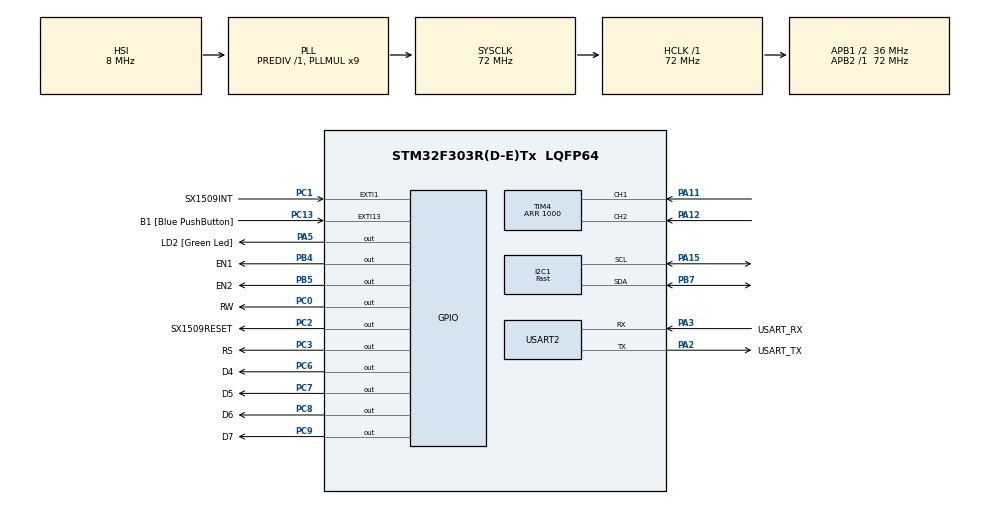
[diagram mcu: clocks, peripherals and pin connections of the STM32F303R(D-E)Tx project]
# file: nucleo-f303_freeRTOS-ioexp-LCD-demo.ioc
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ADC1.Channel-0\#ChannelRegularConversion=ADC_CHANNEL_TEMPSENSOR
ADC1.EnableInjectedConversion=DISABLE
ADC1.NbrOfConversionFlag=1
ADC1.Offset-0\#ChannelRegularConversion=0
ADC1.OffsetNumber-0\#ChannelRegularConversion=ADC_OFFSET_NONE
ADC1.Rank-0\#ChannelRegularConversion=1
ADC1.SamplingTime-0\#ChannelRegularConversion=ADC_SAMPLETIME_181CYCLES_5
ADC1.master=1
FREERTOS.Tasks01=defaultTask,24,128,StartDefaultTask,Default,NULL,Dynamic,NULL,NULL
FREERTOS.configTOTAL_HEAP_SIZE=8096
I2C1.I2C_Speed_Mode=I2C_Fast
I2C1.Timing=0x0000020B
Mcu.Family=STM32F3
Mcu.Name=STM32F303R(D-E)Tx
Mcu.Package=LQFP64
NVIC.ADC1_2_IRQn=true\:5\:0\:false\:false\:true\:true\:true\:true
NVIC.PriorityGroup=NVIC_PRIORITYGROUP_4
NVIC.TIM2_IRQn=true\:5\:0\:false\:false\:true\:true\:true\:true
NVIC.TIM4_IRQn=true\:5\:0\:false\:false\:true\:true\:true\:true
NVIC.TIM6_DAC_IRQn=true\:0\:0\:false\:false\:true\:false\:false\:true
NVIC.TimeBase=TIM6_DAC_IRQn
NVIC.TimeBaseIP=TIM6
PA11.Signal=S_TIM4_CH1
PA12.Signal=S_TIM4_CH2
PA13.GPIO_Label=TMS
PA13.Mode=Serial_Wire
PA13.Signal=SYS_JTMS-SWDIO
PA14.GPIO_Label=TCK
PA14.Mode=Serial_Wire
PA14.Signal=SYS_JTCK-SWCLK
PA15.Mode=I2C
PA15.Signal=I2C1_SCL
PA2.GPIO_Label=USART_TX
PA2.GPIO_Mode=GPIO_MODE_AF_PP
PA2.GPIO_PuPd=GPIO_NOPULL
PA2.GPIO_Speed=GPIO_SPEED_FREQ_LOW
PA2.Mode=Asynchronous
PA2.Signal=USART2_TX
PA3.GPIO_Label=USART_RX
PA3.GPIO_Mode=GPIO_MODE_AF_PP
PA3.GPIO_PuPd=GPIO_NOPULL
PA3.GPIO_Speed=GPIO_SPEED_FREQ_LOW
PA3.Mode=Asynchronous
PA3.Signal=USART2_RX
PA5.GPIO_Label=LD2 [Green Led]
PA5.GPIO_Mode=GPIO_MODE_OUTPUT_PP
PA5.GPIO_PuPd=GPIO_NOPULL
PA5.GPIO_Speed=GPIO_SPEED_FREQ_LOW
PA5.Signal=GPIO_Output
PB3.GPIO_Label=SWO
PB3.Signal=SYS_JTDO-TRACESWO
PB4.GPIO_Label=EN1
PB4.Signal=GPIO_Output
PB5.GPIO_Label=EN2
PB5.Signal=GPIO_Output
PB7.Mode=I2C
PB7.Signal=I2C1_SDA
PC0.GPIO_Label=RW
PC0.Signal=GPIO_Output
PC1.GPIO_Label=SX1509INT
PC1.GPIO_ModeDefaultEXTI=GPIO_MODE_IT_FALLING
PC1.Signal=GPXTI1
PC13.GPIO_Label=B1 [Blue PushButton]
PC13.GPIO_ModeDefaultEXTI=GPIO_MODE_IT_FALLING
PC13.Signal=GPXTI13
PC14-OSC32_IN.Mode=LSE-External-Oscillator
PC14-OSC32_IN.Signal=RCC_OSC32_IN
PC15-OSC32_OUT.Mode=LSE-External-Oscillator
PC15-OSC32_OUT.Signal=RCC_OSC32_OUT
PC2.GPIO_Label=SX1509RESET
PC2.Signal=GPIO_Output
PC3.GPIO_Label=RS
PC3.Signal=GPIO_Output
PC6.GPIO_Label=D4
PC6.Signal=GPIO_Output
PC7.GPIO_Label=D5
PC7.Signal=GPIO_Output
PC8.GPIO_Label=D6
PC8.Signal=GPIO_Output
PC9.GPIO_Label=D7
PC9.Signal=GPIO_Output
PF0-OSC_IN.Mode=HSE-External-Clock-Source
PF0-OSC_IN.Signal=RCC_OSC_IN
PF1-OSC_OUT.Signal=RCC_OSC_OUT
ProjectManager.HeapSize=0x200
ProjectManager.StackSize=0x400
ProjectManager.TargetToolchain=STM32CubeIDE
RCC.AHBFreq_Value=72000000
RCC.APB1CLKDivider=RCC_HCLK_DIV2
RCC.APB1Freq_Value=36000000
RCC.APB1TimFreq_Value=72000000
RCC.APB2Freq_Value=72000000
RCC.APB2TimFreq_Value=72000000
RCC.CortexFreq_Value=72000000
RCC.HCLKFreq_Value=72000000
RCC.HSE_VALUE=8000000
RCC.HSI_VALUE=8000000
RCC.PLLM=8
RCC.PLLMUL=RCC_PLL_MUL9
RCC.PLLN=336
RCC.PLLP=RCC_PLLP_DIV4
RCC.PLLQ=7
RCC.RCC_PLLsource_Clock_Source_FROM_HSE=RCC_HSE_PREDIV_DIV2
RCC.SYSCLKFreq_VALUE=72000000
RCC.SYSCLKSourceVirtual=RCC_SYSCLKSOURCE_PLLCLK
RCC.USBFreq_Value=72000000
SH.S_TIM4_CH1.0=TIM4_CH1,Encoder_Interface
SH.S_TIM4_CH2.0=TIM4_CH2,Encoder_Interface
TIM2.Period=10000
TIM2.Prescaler=7200
TIM2.TIM_MasterOutputTrigger=TIM_TRGO_UPDATE
TIM4.IC1Filter=5
TIM4.IC2Filter=5
TIM4.Period=1000
USART2.VirtualMode-Asynchronous=VM_ASYNC
VP_ADC1_TempSens_Input.Mode=IN-TempSens
VP_FREERTOS_VS_CMSIS_V2.Mode=CMSIS_V2
VP_SYS_VS_tim6.Mode=TIM6
VP_TIM2_VS_ClockSourceINT.Mode=Internal
board=NUCLEO-F303RE

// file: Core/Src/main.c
/* USER CODE BEGIN Header */
/**
  ******************************************************************************
  * @file           : main.c
  * @brief          : Main program body
  ******************************************************************************
  * @attention
  *
  * <h2><center>&copy; Copyright (c) 2020 STMicroelectronics.
  * All rights reserved.</center></h2>
  *
  * This software component is licensed by ST under BSD 3-Clause license,
  * the "License"; You may not use this file except in compliance with the
  * License. You may obtain a copy of the License at:
  *                        opensource.org/licenses/BSD-3-Clause
  *
  ******************************************************************************
  */
/* USER CODE END Header */

#include "main.h"
#include "cmsis_os.h"

ADC_HandleTypeDef hadc1;

I2C_HandleTypeDef hi2c1;

TIM_HandleTypeDef htim2;
TIM_HandleTypeDef htim4;

UART_HandleTypeDef huart2;

/* Definitions for defaultTask */
osThreadId_t defaultTaskHandle;
const osThreadAttr_t defaultTask_attributes = {
  .name = "defaultTask",
  .priority = (osPriority_t) osPriorityNormal,
  .stack_size = 128 * 4
};
/* USER CODE BEGIN PV */
	int32_t encCount;
/* USER CODE END PV */

void SystemClock_Config(void);
static void MX_GPIO_Init(void);
static void MX_USART2_UART_Init(void);
static void MX_TIM4_Init(void);
static void MX_TIM2_Init(void);
static void MX_ADC1_Init(void);
static void MX_I2C1_Init(void);
void StartDefaultTask(void *argument);

int main(void)
{

  /* MCU Configuration--------------------------------------------------------*/

  /* Reset of all peripherals, Initializes the Flash interface and the Systick. */
  HAL_Init();

  /* Configure the system clock */
  SystemClock_Config();

  /* Initialize all configured peripherals */
  MX_GPIO_Init();
  MX_USART2_UART_Init();
  MX_TIM4_Init();
  MX_TIM2_Init();
  MX_ADC1_Init();
  MX_I2C1_Init();
  /* USER CODE BEGIN 2 */
  HAL_TIM_Encoder_Start_IT(&htim4, TIM_CHANNEL_ALL);
  /* USER CODE END 2 */

  /* Init scheduler */
  osKernelInitialize();

  /* Create the thread(s) */
  /* creation of defaultTask */
  defaultTaskHandle = osThreadNew(StartDefaultTask, NULL, &defaultTask_attributes);

  /* Start scheduler */
  osKernelStart();

  /* We should never get here as control is now taken by the scheduler */
  /* Infinite loop */
  while (1)
  {

  }
}

void SystemClock_Config(void)
{
  RCC_OscInitTypeDef RCC_OscInitStruct = {0};
  RCC_ClkInitTypeDef RCC_ClkInitStruct = {0};
  RCC_PeriphCLKInitTypeDef PeriphClkInit = {0};

  /** Initializes the CPU, AHB and APB busses clocks
  */
  RCC_OscInitStruct.OscillatorType = RCC_OSCILLATORTYPE_HSI;
  RCC_OscInitStruct.HSIState = RCC_HSI_ON;
  RCC_OscInitStruct.HSICalibrationValue = RCC_HSICALIBRATION_DEFAULT;
  RCC_OscInitStruct.PLL.PLLState = RCC_PLL_ON;
  RCC_OscInitStruct.PLL.PLLSource = RCC_PLLSOURCE_HSI;
  RCC_OscInitStruct.PLL.PLLMUL = RCC_PLL_MUL9;
  RCC_OscInitStruct.PLL.PREDIV = RCC_PREDIV_DIV1;
  if (HAL_RCC_OscConfig(&RCC_OscInitStruct) != HAL_OK)
  {
    Error_Handler();
  }
  /** Initializes the CPU, AHB and APB busses clocks
  */
  RCC_ClkInitStruct.ClockType = RCC_CLOCKTYPE_HCLK|RCC_CLOCKTYPE_SYSCLK
                              |RCC_CLOCKTYPE_PCLK1|RCC_CLOCKTYPE_PCLK2;
  RCC_ClkInitStruct.SYSCLKSource = RCC_SYSCLKSOURCE_PLLCLK;
  RCC_ClkInitStruct.AHBCLKDivider = RCC_SYSCLK_DIV1;
  RCC_ClkInitStruct.APB1CLKDivider = RCC_HCLK_DIV2;
  RCC_ClkInitStruct.APB2CLKDivider = RCC_HCLK_DIV1;

  if (HAL_RCC_ClockConfig(&RCC_ClkInitStruct, FLASH_LATENCY_2) != HAL_OK)
  {
    Error_Handler();
  }
  PeriphClkInit.PeriphClockSelection = RCC_PERIPHCLK_USART2|RCC_PERIPHCLK_I2C1
                              |RCC_PERIPHCLK_ADC12|RCC_PERIPHCLK_TIM2
                              |RCC_PERIPHCLK_TIM34;
  PeriphClkInit.Usart2ClockSelection = RCC_USART2CLKSOURCE_PCLK1;
  PeriphClkInit.Adc12ClockSelection = RCC_ADC12PLLCLK_DIV1;
  PeriphClkInit.I2c1ClockSelection = RCC_I2C1CLKSOURCE_HSI;
  PeriphClkInit.Tim2ClockSelection = RCC_TIM2CLK_HCLK;
  PeriphClkInit.Tim34ClockSelection = RCC_TIM34CLK_HCLK;
  if (HAL_RCCEx_PeriphCLKConfig(&PeriphClkInit) != HAL_OK)
  {
    Error_Handler();
  }
}

static void MX_ADC1_Init(void)
{

  ADC_MultiModeTypeDef multimode = {0};
  ADC_ChannelConfTypeDef sConfig = {0};

  /** Common config
  */
  hadc1.Instance = ADC1;
  hadc1.Init.ClockPrescaler = ADC_CLOCK_ASYNC_DIV1;
  hadc1.Init.Resolution = ADC_RESOLUTION_12B;
  hadc1.Init.ScanConvMode = ADC_SCAN_DISABLE;
  hadc1.Init.ContinuousConvMode = DISABLE;
  hadc1.Init.DiscontinuousConvMode = DISABLE;
  hadc1.Init.ExternalTrigConvEdge = ADC_EXTERNALTRIGCONVEDGE_NONE;
  hadc1.Init.ExternalTrigConv = ADC_SOFTWARE_START;
  hadc1.Init.DataAlign = ADC_DATAALIGN_RIGHT;
  hadc1.Init.NbrOfConversion = 1;
  hadc1.Init.DMAContinuousRequests = DISABLE;
  hadc1.Init.EOCSelection = ADC_EOC_SINGLE_CONV;
  hadc1.Init.LowPowerAutoWait = DISABLE;
  hadc1.Init.Overrun = ADC_OVR_DATA_OVERWRITTEN;
  if (HAL_ADC_Init(&hadc1) != HAL_OK)
  {
    Error_Handler();
  }
  /** Configure the ADC multi-mode
  */
  multimode.Mode = ADC_MODE_INDEPENDENT;
  if (HAL_ADCEx_MultiModeConfigChannel(&hadc1, &multimode) != HAL_OK)
  {
    Error_Handler();
  }
  /** Configure Regular Channel
  */
  sConfig.Channel = ADC_CHANNEL_TEMPSENSOR;
  sConfig.Rank = ADC_REGULAR_RANK_1;
  sConfig.SingleDiff = ADC_SINGLE_ENDED;
  sConfig.SamplingTime = ADC_SAMPLETIME_181CYCLES_5;
  sConfig.OffsetNumber = ADC_OFFSET_NONE;
  sConfig.Offset = 0;
  if (HAL_ADC_ConfigChannel(&hadc1, &sConfig) != HAL_OK)
  {
    Error_Handler();
  }

}

static void MX_I2C1_Init(void)
{

  hi2c1.Instance = I2C1;
  hi2c1.Init.Timing = 0x0000020B;
  hi2c1.Init.OwnAddress1 = 0;
  hi2c1.Init.AddressingMode = I2C_ADDRESSINGMODE_7BIT;
  hi2c1.Init.DualAddressMode = I2C_DUALADDRESS_DISABLE;
  hi2c1.Init.OwnAddress2 = 0;
  hi2c1.Init.OwnAddress2Masks = I2C_OA2_NOMASK;
  hi2c1.Init.GeneralCallMode = I2C_GENERALCALL_DISABLE;
  hi2c1.Init.NoStretchMode = I2C_NOSTRETCH_DISABLE;
  if (HAL_I2C_Init(&hi2c1) != HAL_OK)
  {
    Error_Handler();
  }
  /** Configure Analogue filter
  */
  if (HAL_I2CEx_ConfigAnalogFilter(&hi2c1, I2C_ANALOGFILTER_ENABLE) != HAL_OK)
  {
    Error_Handler();
  }
  /** Configure Digital filter
  */
  if (HAL_I2CEx_ConfigDigitalFilter(&hi2c1, 0) != HAL_OK)
  {
    Error_Handler();
  }

}

static void MX_TIM2_Init(void)
{

  TIM_ClockConfigTypeDef sClockSourceConfig = {0};
  TIM_MasterConfigTypeDef sMasterConfig = {0};

  htim2.Instance = TIM2;
  htim2.Init.Prescaler = 7200;
  htim2.Init.CounterMode = TIM_COUNTERMODE_UP;
  htim2.Init.Period = 10000;
  htim2.Init.ClockDivision = TIM_CLOCKDIVISION_DIV1;
  htim2.Init.AutoReloadPreload = TIM_AUTORELOAD_PRELOAD_DISABLE;
  if (HAL_TIM_Base_Init(&htim2) != HAL_OK)
  {
    Error_Handler();
  }
  sClockSourceConfig.ClockSource = TIM_CLOCKSOURCE_INTERNAL;
  if (HAL_TIM_ConfigClockSource(&htim2, &sClockSourceConfig) != HAL_OK)
  {
    Error_Handler();
  }
  sMasterConfig.MasterOutputTrigger = TIM_TRGO_UPDATE;
  sMasterConfig.MasterSlaveMode = TIM_MASTERSLAVEMODE_DISABLE;
  if (HAL_TIMEx_MasterConfigSynchronization(&htim2, &sMasterConfig) != HAL_OK)
  {
    Error_Handler();
  }

}

static void MX_TIM4_Init(void)
{

  TIM_Encoder_InitTypeDef sConfig = {0};
  TIM_MasterConfigTypeDef sMasterConfig = {0};

  htim4.Instance = TIM4;
  htim4.Init.Prescaler = 0;
  htim4.Init.CounterMode = TIM_COUNTERMODE_UP;
  htim4.Init.Period = 1000;
  htim4.Init.ClockDivision = TIM_CLOCKDIVISION_DIV1;
  htim4.Init.AutoReloadPreload = TIM_AUTORELOAD_PRELOAD_DISABLE;
  sConfig.EncoderMode = TIM_ENCODERMODE_TI1;
  sConfig.IC1Polarity = TIM_ICPOLARITY_RISING;
  sConfig.IC1Selection = TIM_ICSELECTION_DIRECTTI;
  sConfig.IC1Prescaler = TIM_ICPSC_DIV1;
  sConfig.IC1Filter = 5;
  sConfig.IC2Polarity = TIM_ICPOLARITY_RISING;
  sConfig.IC2Selection = TIM_ICSELECTION_DIRECTTI;
  sConfig.IC2Prescaler = TIM_ICPSC_DIV1;
  sConfig.IC2Filter = 5;
  if (HAL_TIM_Encoder_Init(&htim4, &sConfig) != HAL_OK)
  {
    Error_Handler();
  }
  sMasterConfig.MasterOutputTrigger = TIM_TRGO_RESET;
  sMasterConfig.MasterSlaveMode = TIM_MASTERSLAVEMODE_DISABLE;
  if (HAL_TIMEx_MasterConfigSynchronization(&htim4, &sMasterConfig) != HAL_OK)
  {
    Error_Handler();
  }

}

static void MX_USART2_UART_Init(void)
{

  huart2.Instance = USART2;
  huart2.Init.BaudRate = 38400;
  huart2.Init.WordLength = UART_WORDLENGTH_8B;
  huart2.Init.StopBits = UART_STOPBITS_1;
  huart2.Init.Parity = UART_PARITY_NONE;
  huart2.Init.Mode = UART_MODE_TX_RX;
  huart2.Init.HwFlowCtl = UART_HWCONTROL_NONE;
  huart2.Init.OverSampling = UART_OVERSAMPLING_16;
  huart2.Init.OneBitSampling = UART_ONE_BIT_SAMPLE_DISABLE;
  huart2.AdvancedInit.AdvFeatureInit = UART_ADVFEATURE_NO_INIT;
  if (HAL_UART_Init(&huart2) != HAL_OK)
  {
    Error_Handler();
  }

}

static void MX_GPIO_Init(void)
{
  GPIO_InitTypeDef GPIO_InitStruct = {0};

  /* GPIO Ports Clock Enable */
  __HAL_RCC_GPIOC_CLK_ENABLE();
  __HAL_RCC_GPIOF_CLK_ENABLE();
  __HAL_RCC_GPIOA_CLK_ENABLE();
  __HAL_RCC_GPIOB_CLK_ENABLE();

  /*Configure GPIO pin Output Level */
  HAL_GPIO_WritePin(GPIOC, RW_Pin|SX1509RESET_Pin|RS_Pin|D4_Pin
                          |D5_Pin|D6_Pin|D7_Pin, GPIO_PIN_RESET);

  /*Configure GPIO pin Output Level */
  HAL_GPIO_WritePin(LD2_GPIO_Port, LD2_Pin, GPIO_PIN_RESET);

  /*Configure GPIO pin Output Level */
  HAL_GPIO_WritePin(GPIOB, EN1_Pin|EN2_Pin, GPIO_PIN_RESET);

  /*Configure GPIO pins : B1_Pin SX1509INT_Pin */
  GPIO_InitStruct.Pin = B1_Pin|SX1509INT_Pin;
  GPIO_InitStruct.Mode = GPIO_MODE_IT_FALLING;
  GPIO_InitStruct.Pull = GPIO_NOPULL;
  HAL_GPIO_Init(GPIOC, &GPIO_InitStruct);

  /*Configure GPIO pins : RW_Pin SX1509RESET_Pin RS_Pin D4_Pin
                           D5_Pin D6_Pin D7_Pin */
  GPIO_InitStruct.Pin = RW_Pin|SX1509RESET_Pin|RS_Pin|D4_Pin
                          |D5_Pin|D6_Pin|D7_Pin;
  GPIO_InitStruct.Mode = GPIO_MODE_OUTPUT_PP;
  GPIO_InitStruct.Pull = GPIO_NOPULL;
  GPIO_InitStruct.Speed = GPIO_SPEED_FREQ_LOW;
  HAL_GPIO_Init(GPIOC, &GPIO_InitStruct);

  /*Configure GPIO pin : LD2_Pin */
  GPIO_InitStruct.Pin = LD2_Pin;
  GPIO_InitStruct.Mode = GPIO_MODE_OUTPUT_PP;
  GPIO_InitStruct.Pull = GPIO_NOPULL;
  GPIO_InitStruct.Speed = GPIO_SPEED_FREQ_LOW;
  HAL_GPIO_Init(LD2_GPIO_Port, &GPIO_InitStruct);

  /*Configure GPIO pins : EN1_Pin EN2_Pin */
  GPIO_InitStruct.Pin = EN1_Pin|EN2_Pin;
  GPIO_InitStruct.Mode = GPIO_MODE_OUTPUT_PP;
  GPIO_InitStruct.Pull = GPIO_NOPULL;
  GPIO_InitStruct.Speed = GPIO_SPEED_FREQ_LOW;
  HAL_GPIO_Init(GPIOB, &GPIO_InitStruct);

}

void StartDefaultTask(void *argument)
{
  for(;;)
  {
    osDelay(1);
  }
}

 /**
  * @brief  Period elapsed callback in non blocking mode
  * @note   This function is called  when TIM6 interrupt took place, inside
  * HAL_TIM_IRQHandler(). It makes a direct call to HAL_IncTick() to increment
  * a global variable "uwTick" used as application time base.
  * @param  htim : TIM handle
  * @retval None
  */
void HAL_TIM_PeriodElapsedCallback(TIM_HandleTypeDef *htim)
{
  if (htim->Instance == TIM6) {
    HAL_IncTick();
  }
}

void Error_Handler(void)
{
}

/************************ (C) COPYRIGHT STMicroelectronics *****END OF FILE****/
